// Description: LIN Description file created using Vector's Network Designer

// Created: 12 Mar 2013 16:30:13

// Author: u074570

LIN_description_file;
LIN_protocol_version = "1.3";
LIN_language_version = "1.3";
LIN_speed = 9.6 kbps;

Nodes {
  Master: NodeBSGEvo, 5 ms, 0.1 ms;
  Slaves: NodeDNR, NodeMFL, Tester ;
}

Signals {
  DNR_Position_RM: 1, 0, NodeDNR, NodeBSGEvo ;
  DNR_Position_R1: 1, 0, NodeDNR, NodeBSGEvo ;
  DNR_Position_N: 1, 0, NodeDNR, NodeBSGEvo ;
  DNR_Position_D1: 1, 0, NodeDNR, NodeBSGEvo ;
  DNR_Position_D4: 1, 0, NodeDNR, NodeBSGEvo ;
  DNR_Position_D7: 1, 0, NodeDNR, NodeBSGEvo ;
  DNR_Position_DM: 1, 0, NodeDNR, NodeBSGEvo ;
  DNR_Position_MsgCounter: 4, 0, NodeDNR, NodeBSGEvo ;
  DNR_Position_SwitchStatus: 4, 0, NodeDNR, NodeBSGEvo ;
  MFL_Version_Hw: 4, 0, NodeMFL ;
  MFL_Version_Sw: 4, 0, NodeMFL ;
  MFL_BtnInfo_Btn1: 1, 0, NodeMFL, NodeBSGEvo ;
  MFL_BtnInfo_Btn10: 1, 0, NodeMFL, NodeBSGEvo ;
  MFL_BtnInfo_Btn2: 1, 0, NodeMFL, NodeBSGEvo ;
  MFL_BtnInfo_Btn3: 1, 0, NodeMFL, NodeBSGEvo ;
  MFL_BtnInfo_Btn3LPress: 1, 0, NodeMFL, NodeBSGEvo ;
  MFL_BtnInfo_Btn3SPress: 1, 0, NodeMFL, NodeBSGEvo ;
  MFL_BtnInfo_Btn4: 1, 0, NodeMFL, NodeBSGEvo ;
  MFL_BtnInfo_Btn4LPress: 1, 0, NodeMFL, NodeBSGEvo ;
  MFL_BtnInfo_Btn4SPress: 1, 0, NodeMFL, NodeBSGEvo ;
  MFL_BtnInfo_Btn5: 1, 0, NodeMFL, NodeBSGEvo ;
  MFL_BtnInfo_Btn5LPress: 1, 0, NodeMFL, NodeBSGEvo ;
  MFL_BtnInfo_Btn5SPress: 1, 0, NodeMFL, NodeBSGEvo ;
  MFL_BtnInfo_Btn6: 1, 0, NodeMFL, NodeBSGEvo ;
  MFL_BtnInfo_Btn7: 1, 0, NodeMFL, NodeBSGEvo ;
  MFL_BtnInfo_Btn8: 1, 0, NodeMFL, NodeBSGEvo ;
  MFL_BtnInfo_Btn9: 1, 0, NodeMFL, NodeBSGEvo ;
  MFL_BtnInfo_ErrorLoc: 4, 0, NodeMFL, NodeBSGEvo ;
  MFL_BtnInfo_ErrorType: 4, 0, NodeMFL, NodeBSGEvo ;
  MFL_BtnInfo_MsgCounter: 4, 0, NodeMFL, NodeBSGEvo ;
  BSGEvo_Illumi_DutyCycle: 8, 0, NodeBSGEvo, NodeMFL ;
  Button_KL15: 1, 0, NodeBSGEvo, Tester ;
  Voltage_Normal: 1, 0, NodeBSGEvo, Tester ;
  Voltage_OV1: 1, 0, NodeBSGEvo, Tester ;
  Voltage_OV2: 1, 0, NodeBSGEvo, Tester ;
  Voltage_UV1: 1, 0, NodeBSGEvo, Tester ;
  Voltage_UV2: 1, 0, NodeBSGEvo, Tester ;
  BatteryVoltage: 16, 0, NodeBSGEvo, Tester ;
  ResponseErrorTester: 1, 0, Tester, NodeBSGEvo ;
}

Frames {
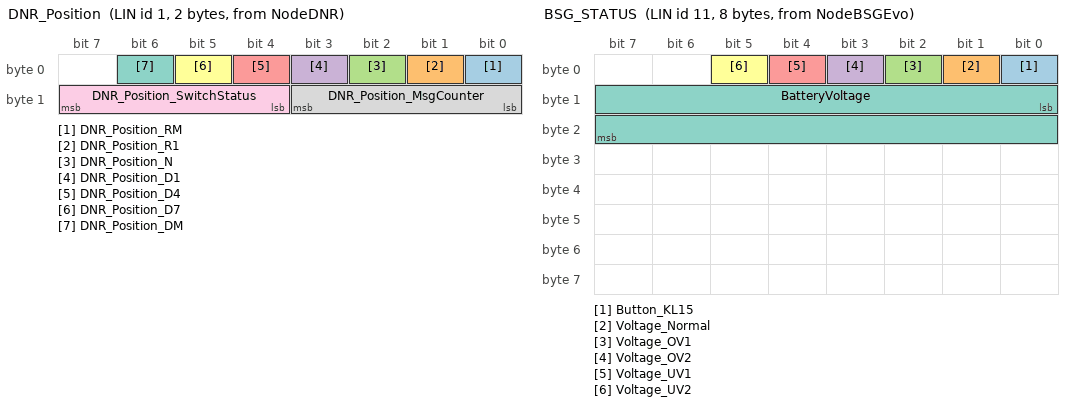
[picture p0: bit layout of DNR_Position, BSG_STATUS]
  DNR_Position: 1, NodeDNR, 2 {
    DNR_Position_RM, 0 ;
    DNR_Position_R1, 1 ;
    DNR_Position_N, 2 ;
    DNR_Position_D1, 3 ;
    DNR_Position_D4, 4 ;
    DNR_Position_D7, 5 ;
    DNR_Position_DM, 6 ;
    DNR_Position_MsgCounter, 8 ;
    DNR_Position_SwitchStatus, 12 ;
  }

  MFL_BtnInfo: 33, NodeMFL, 4 {
    MFL_BtnInfo_MsgCounter, 0 ;
    MFL_BtnInfo_ErrorType, 8 ;
    MFL_BtnInfo_ErrorLoc, 12 ;
    MFL_BtnInfo_Btn1, 16 ;
    MFL_BtnInfo_Btn2, 17 ;
    MFL_BtnInfo_Btn3, 18 ;
    MFL_BtnInfo_Btn4, 19 ;
    MFL_BtnInfo_Btn5, 20 ;
    MFL_BtnInfo_Btn6, 21 ;
    MFL_BtnInfo_Btn7, 22 ;
    MFL_BtnInfo_Btn8, 23 ;
    MFL_BtnInfo_Btn9, 24 ;
    MFL_BtnInfo_Btn10, 25 ;
    MFL_BtnInfo_Btn3SPress, 26 ;
    MFL_BtnInfo_Btn3LPress, 27 ;
    MFL_BtnInfo_Btn4SPress, 28 ;
    MFL_BtnInfo_Btn4LPress, 29 ;
    MFL_BtnInfo_Btn5SPress, 30 ;
    MFL_BtnInfo_Btn5LPress, 31 ;
  }

  BSGEvo_Illumi: 3, NodeBSGEvo, 2 {
    BSGEvo_Illumi_DutyCycle, 0 ;
  }

  BSG_STATUS: 11, NodeBSGEvo, 8 {
    Button_KL15, 0 ;
    Voltage_Normal, 1 ;
    Voltage_OV1, 2 ;
    Voltage_OV2, 3 ;
    Voltage_UV1, 4 ;
    Voltage_UV2, 5 ;
    BatteryVoltage, 8 ;
  }
  TESTER_STATUS: 12, Tester, 1 {
    ResponseErrorTester, 0 ;
  }
}

Node_attributes {
  NodeDNR {
    LIN_protocol = "1.3";
    configured_NAD = 0x20;
  response_error = DNR_Position_R1;
  }

  NodeMFL {
    LIN_protocol = "1.3";
    configured_NAD = 0x21;
  response_error = MFL_BtnInfo_Btn1;
  }

  Tester{
    LIN_protocol = "1.3" ;
    configured_NAD = 0x17 ;
    initial_NAD = 0x17 ;
    product_id = 0x0, 0x0, 0 ;
    response_error = ResponseErrorTester ;
    P2_min = 50 ms ;
    ST_min = 0 ms ;
    N_As_timeout = 1000 ms ;
    N_Cr_timeout = 1000 ms ;
    configurable_frames {
      BSG_STATUS ;
      TESTER_STATUS ;
    }
  }
}

Schedule_tables {
 STDNR {
    DNR_Position delay 50 ms ;
  }
 STMFL {
    MFL_BtnInfo delay 20 ms ;
    BSGEvo_Illumi delay 20 ms ;
 }
 DEFAULTTABLE {
    BSG_STATUS delay 100 ms ;
    TESTER_STATUS delay 100 ms ;
  }
}

Signal_encoding_types {
  BSGEvo_Illumi_DutyCycle_Encoding {
    physical_value, 0, 250, 0.4, 0, "%" ;
    logical_value, 251, "Parameter Specific Indicator" ;
    logical_value, 252, "Reserved Range For Future Indication" ;
    logical_value, 253, "Reserved Range For Future Indication" ;
    logical_value, 254, "Error Indicator" ;
    logical_value, 255, "Not Available" ;
  }
  DNR_Position_MsgCounter_Encoding {
    physical_value, 0, 15, 1, 0 ;
  }
  DNR_Position_Selected_Encoding {
    physical_value, 0, 1, 1, 0 ;
    logical_value, 0, "NonSelected" ;
    logical_value, 1, "Selected" ;
  }
  DNR_Position_SwitchStatus_Encoding {
    physical_value, 0, 15, 1, 0 ;
    logical_value, 0, "Switch Position Valid" ;
    logical_value, 1, "2 Contiguous Switching Positions Active" ;
    logical_value, 2, "Switch Defect" ;
    logical_value, 3, "Signal Not Available" ;
  }
  MFL_BtnInfo_Btn_Encoding {
    physical_value, 0, 1, 1, 0 ;
    logical_value, 0, "Inactive" ;
    logical_value, 1, "Active" ;
  }
  MFL_BtnInfo_ErrorLoc_Encoding {
    physical_value, 0, 15, 1, 0 ;
    logical_value, 2, "MFL right out of order" ;
    logical_value, 8, "MFL left out of order" ;
    logical_value, 10, "MFL right and left out of order" ;
  }
  MFL_BtnInfo_ErrorType_Encoding {
    physical_value, 0, 15, 1, 0 ;
    logical_value, 15, "Not Available" ;
  }
  MFL_BtnInfo_MsgCounter_Encoding {
    physical_value, 0, 15, 1, 0 ;
  }
  MFL_Version_4bit_Encoding {
    physical_value, 0, 15, 1, 0 ;
  }
  ButtonSts_Encoding {
    logical_value, 0, "Button released" ;
    logical_value, 1, "Button pressed" ;
  }
  ResponseError_Sig_Type {
    logical_value, 0, "Node_Is_Operating_Correctly" ;
    logical_value, 1, "Node_Has_Intermittent_Problems" ;
  }
}

Signal_representation {
  BSGEvo_Illumi_DutyCycle_Encoding: BSGEvo_Illumi_DutyCycle ;
  DNR_Position_MsgCounter_Encoding: DNR_Position_MsgCounter ;
  DNR_Position_Selected_Encoding: DNR_Position_RM, DNR_Position_R1, DNR_Position_N, DNR_Position_D1, DNR_Position_D4, DNR_Position_D7, DNR_Position_DM ;
  DNR_Position_SwitchStatus_Encoding: DNR_Position_SwitchStatus ;
  MFL_BtnInfo_Btn_Encoding: MFL_BtnInfo_Btn1, MFL_BtnInfo_Btn10, MFL_BtnInfo_Btn2, MFL_BtnInfo_Btn3, MFL_BtnInfo_Btn3LPress, MFL_BtnInfo_Btn3SPress, MFL_BtnInfo_Btn4, MFL_BtnInfo_Btn4LPress, MFL_BtnInfo_Btn4SPress, MFL_BtnInfo_Btn5, MFL_BtnInfo_Btn5LPress, MFL_BtnInfo_Btn5SPress, MFL_BtnInfo_Btn6, MFL_BtnInfo_Btn7, MFL_BtnInfo_Btn8, MFL_BtnInfo_Btn9 ;
  MFL_BtnInfo_ErrorLoc_Encoding: MFL_BtnInfo_ErrorLoc ;
  MFL_BtnInfo_ErrorType_Encoding: MFL_BtnInfo_ErrorType ;
  MFL_BtnInfo_MsgCounter_Encoding: MFL_BtnInfo_MsgCounter ;
  MFL_Version_4bit_Encoding: MFL_Version_Hw, MFL_Version_Sw ;
  ButtonSts_Encoding: Button_KL15 ;
}
